VERSION ""

NS_ :

BS_:

BU_:

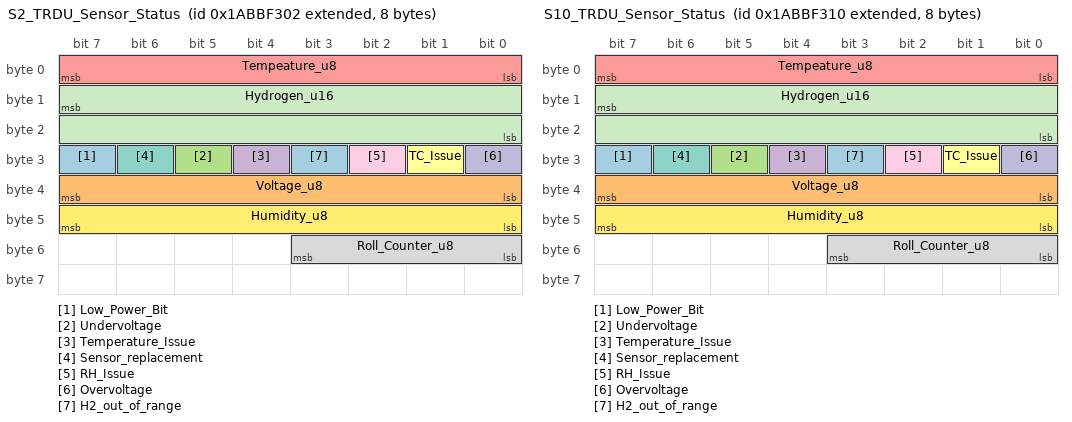
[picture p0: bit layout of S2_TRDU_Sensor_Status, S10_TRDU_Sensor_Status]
BO_ 2596008706 S2_TRDU_Sensor_Status: 8 Vector__XXX
 SG_ Low_Power_Bit : 31|1@1+ (1,0) [0|0] "" Vector__XXX
 SG_ Voltage_u8 : 39|8@0+ (0.2,0) [0|25.5] "V" Vector__XXX
 SG_ Undervoltage : 29|1@1+ (1,0) [0|0] "" Vector__XXX
 SG_ Temperature_Issue : 28|1@1+ (1,0) [0|0] "" Vector__XXX
 SG_ Tempeature_u8 : 0|8@1+ (1,-55) [-55|195] "°C" Vector__XXX
 SG_ TC_Issue : 25|1@1+ (1,0) [0|0] "" Vector__XXX
 SG_ Sensor_replacement : 30|1@1+ (1,0) [0|0] "" Vector__XXX
 SG_ Roll_Counter_u8 : 51|4@0+ (1,0) [0|15] "" Vector__XXX
 SG_ RH_Issue : 26|1@1+ (1,0) [0|0] "" Vector__XXX
 SG_ Overvoltage : 24|1@1+ (1,0) [0|0] "" Vector__XXX
 SG_ Hydrogen_u16 : 15|16@0+ (0.01,0) [0|100] "%" Vector__XXX
 SG_ Humidity_u8 : 47|8@0+ (0.5,0) [0|100] "%" Vector__XXX
 SG_ H2_out_of_range : 27|1@1+ (1,0) [0|0] "" Vector__XXX

BO_ 2596008720 S10_TRDU_Sensor_Status: 8 Vector__XXX
 SG_ Low_Power_Bit : 31|1@1+ (1,0) [0|0] "" Vector__XXX
 SG_ Voltage_u8 : 39|8@0+ (0.2,0) [0|25.5] "V" Vector__XXX
 SG_ Undervoltage : 29|1@1+ (1,0) [0|0] "" Vector__XXX
 SG_ Temperature_Issue : 28|1@1+ (1,0) [0|0] "" Vector__XXX
 SG_ Tempeature_u8 : 0|8@1+ (1,-55) [-55|195] "°C" Vector__XXX
 SG_ TC_Issue : 25|1@1+ (1,0) [0|0] "" Vector__XXX
 SG_ Sensor_replacement : 30|1@1+ (1,0) [0|0] "" Vector__XXX
 SG_ Roll_Counter_u8 : 51|4@0+ (1,0) [0|15] "" Vector__XXX
 SG_ RH_Issue : 26|1@1+ (1,0) [0|0] "" Vector__XXX
 SG_ Overvoltage : 24|1@1+ (1,0) [0|0] "" Vector__XXX
 SG_ Hydrogen_u16 : 15|16@0+ (0.01,0) [0|100] "%" Vector__XXX
 SG_ Humidity_u8 : 47|8@0+ (0.5,0) [0|100] "%" Vector__XXX
 SG_ H2_out_of_range : 27|1@1+ (1,0) [0|0] "" Vector__XXX

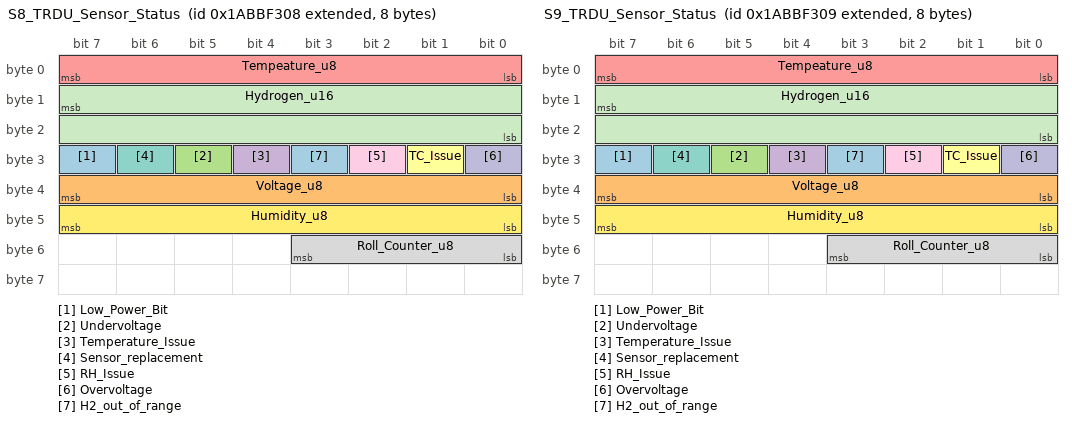
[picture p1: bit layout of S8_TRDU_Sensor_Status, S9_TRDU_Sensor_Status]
BO_ 2596008712 S8_TRDU_Sensor_Status: 8 Vector__XXX
 SG_ Low_Power_Bit : 31|1@1+ (1,0) [0|0] "" Vector__XXX
 SG_ Voltage_u8 : 39|8@0+ (0.2,0) [0|25.5] "V" Vector__XXX
 SG_ Undervoltage : 29|1@1+ (1,0) [0|0] "" Vector__XXX
 SG_ Temperature_Issue : 28|1@1+ (1,0) [0|0] "" Vector__XXX
 SG_ Tempeature_u8 : 0|8@1+ (1,-55) [-55|195] "°C" Vector__XXX
 SG_ TC_Issue : 25|1@1+ (1,0) [0|0] "" Vector__XXX
 SG_ Sensor_replacement : 30|1@1+ (1,0) [0|0] "" Vector__XXX
 SG_ Roll_Counter_u8 : 51|4@0+ (1,0) [0|15] "" Vector__XXX
 SG_ RH_Issue : 26|1@1+ (1,0) [0|0] "" Vector__XXX
 SG_ Overvoltage : 24|1@1+ (1,0) [0|0] "" Vector__XXX
 SG_ Hydrogen_u16 : 15|16@0+ (0.01,0) [0|100] "%" Vector__XXX
 SG_ Humidity_u8 : 47|8@0+ (0.5,0) [0|100] "%" Vector__XXX
 SG_ H2_out_of_range : 27|1@1+ (1,0) [0|0] "" Vector__XXX

BO_ 2596008713 S9_TRDU_Sensor_Status: 8 Vector__XXX
 SG_ Low_Power_Bit : 31|1@1+ (1,0) [0|0] "" Vector__XXX
 SG_ Voltage_u8 : 39|8@0+ (0.2,0) [0|25.5] "V" Vector__XXX
 SG_ Undervoltage : 29|1@1+ (1,0) [0|0] "" Vector__XXX
 SG_ Temperature_Issue : 28|1@1+ (1,0) [0|0] "" Vector__XXX
 SG_ Tempeature_u8 : 0|8@1+ (1,-55) [-55|195] "°C" Vector__XXX
 SG_ TC_Issue : 25|1@1+ (1,0) [0|0] "" Vector__XXX
 SG_ Sensor_replacement : 30|1@1+ (1,0) [0|0] "" Vector__XXX
 SG_ Roll_Counter_u8 : 51|4@0+ (1,0) [0|15] "" Vector__XXX
 SG_ RH_Issue : 26|1@1+ (1,0) [0|0] "" Vector__XXX
 SG_ Overvoltage : 24|1@1+ (1,0) [0|0] "" Vector__XXX
 SG_ Hydrogen_u16 : 15|16@0+ (0.01,0) [0|100] "%" Vector__XXX
 SG_ Humidity_u8 : 47|8@0+ (0.5,0) [0|100] "%" Vector__XXX
 SG_ H2_out_of_range : 27|1@1+ (1,0) [0|0] "" Vector__XXX

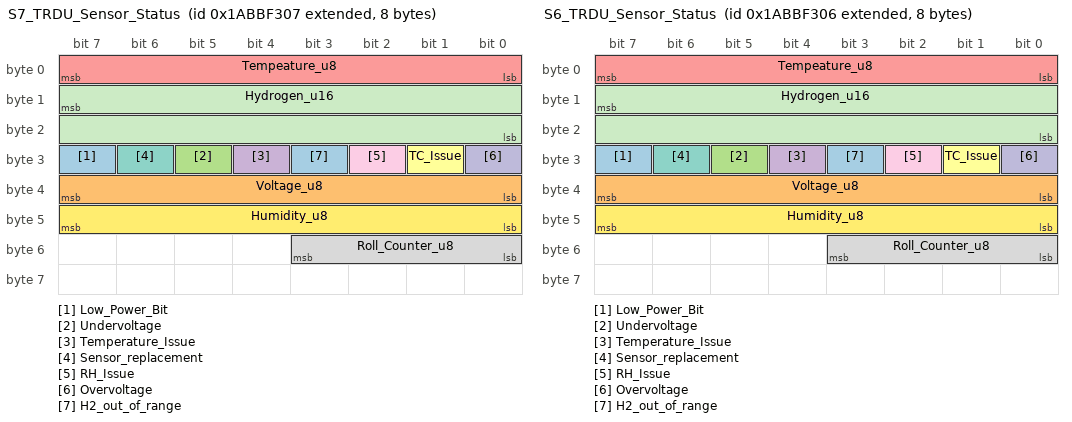
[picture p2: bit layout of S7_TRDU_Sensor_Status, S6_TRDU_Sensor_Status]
BO_ 2596008711 S7_TRDU_Sensor_Status: 8 Vector__XXX
 SG_ Low_Power_Bit : 31|1@1+ (1,0) [0|0] "" Vector__XXX
 SG_ Voltage_u8 : 39|8@0+ (0.2,0) [0|25.5] "V" Vector__XXX
 SG_ Undervoltage : 29|1@1+ (1,0) [0|0] "" Vector__XXX
 SG_ Temperature_Issue : 28|1@1+ (1,0) [0|0] "" Vector__XXX
 SG_ Tempeature_u8 : 0|8@1+ (1,-55) [-55|195] "°C" Vector__XXX
 SG_ TC_Issue : 25|1@1+ (1,0) [0|0] "" Vector__XXX
 SG_ Sensor_replacement : 30|1@1+ (1,0) [0|0] "" Vector__XXX
 SG_ Roll_Counter_u8 : 51|4@0+ (1,0) [0|15] "" Vector__XXX
 SG_ RH_Issue : 26|1@1+ (1,0) [0|0] "" Vector__XXX
 SG_ Overvoltage : 24|1@1+ (1,0) [0|0] "" Vector__XXX
 SG_ Hydrogen_u16 : 15|16@0+ (0.01,0) [0|100] "%" Vector__XXX
 SG_ Humidity_u8 : 47|8@0+ (0.5,0) [0|100] "%" Vector__XXX
 SG_ H2_out_of_range : 27|1@1+ (1,0) [0|0] "" Vector__XXX

BO_ 2596008710 S6_TRDU_Sensor_Status: 8 Vector__XXX
 SG_ Low_Power_Bit : 31|1@1+ (1,0) [0|0] "" Vector__XXX
 SG_ Voltage_u8 : 39|8@0+ (0.2,0) [0|25.5] "V" Vector__XXX
 SG_ Undervoltage : 29|1@1+ (1,0) [0|0] "" Vector__XXX
 SG_ Temperature_Issue : 28|1@1+ (1,0) [0|0] "" Vector__XXX
 SG_ Tempeature_u8 : 0|8@1+ (1,-55) [-55|195] "°C" Vector__XXX
 SG_ TC_Issue : 25|1@1+ (1,0) [0|0] "" Vector__XXX
 SG_ Sensor_replacement : 30|1@1+ (1,0) [0|0] "" Vector__XXX
 SG_ Roll_Counter_u8 : 51|4@0+ (1,0) [0|15] "" Vector__XXX
 SG_ RH_Issue : 26|1@1+ (1,0) [0|0] "" Vector__XXX
 SG_ Overvoltage : 24|1@1+ (1,0) [0|0] "" Vector__XXX
 SG_ Hydrogen_u16 : 15|16@0+ (0.01,0) [0|100] "%" Vector__XXX
 SG_ Humidity_u8 : 47|8@0+ (0.5,0) [0|100] "%" Vector__XXX
 SG_ H2_out_of_range : 27|1@1+ (1,0) [0|0] "" Vector__XXX

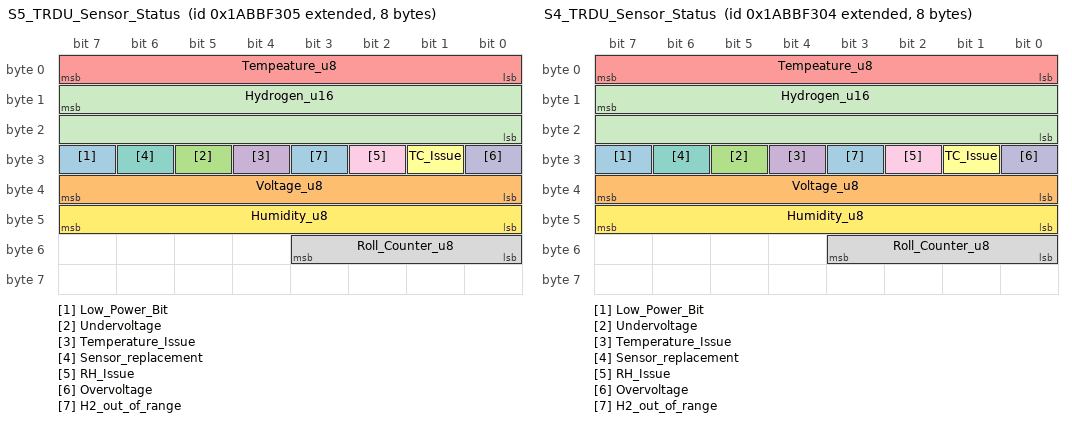
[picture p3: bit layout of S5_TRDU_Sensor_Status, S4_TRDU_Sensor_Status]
BO_ 2596008709 S5_TRDU_Sensor_Status: 8 Vector__XXX
 SG_ Low_Power_Bit : 31|1@1+ (1,0) [0|0] "" Vector__XXX
 SG_ Voltage_u8 : 39|8@0+ (0.2,0) [0|25.5] "V" Vector__XXX
 SG_ Undervoltage : 29|1@1+ (1,0) [0|0] "" Vector__XXX
 SG_ Temperature_Issue : 28|1@1+ (1,0) [0|0] "" Vector__XXX
 SG_ Tempeature_u8 : 0|8@1+ (1,-55) [-55|195] "°C" Vector__XXX
 SG_ TC_Issue : 25|1@1+ (1,0) [0|0] "" Vector__XXX
 SG_ Sensor_replacement : 30|1@1+ (1,0) [0|0] "" Vector__XXX
 SG_ Roll_Counter_u8 : 51|4@0+ (1,0) [0|15] "" Vector__XXX
 SG_ RH_Issue : 26|1@1+ (1,0) [0|0] "" Vector__XXX
 SG_ Overvoltage : 24|1@1+ (1,0) [0|0] "" Vector__XXX
 SG_ Hydrogen_u16 : 15|16@0+ (0.01,0) [0|100] "%" Vector__XXX
 SG_ Humidity_u8 : 47|8@0+ (0.5,0) [0|100] "%" Vector__XXX
 SG_ H2_out_of_range : 27|1@1+ (1,0) [0|0] "" Vector__XXX

BO_ 2596008708 S4_TRDU_Sensor_Status: 8 Vector__XXX
 SG_ Low_Power_Bit : 31|1@1+ (1,0) [0|0] "" Vector__XXX
 SG_ Voltage_u8 : 39|8@0+ (0.2,0) [0|25.5] "V" Vector__XXX
 SG_ Undervoltage : 29|1@1+ (1,0) [0|0] "" Vector__XXX
 SG_ Temperature_Issue : 28|1@1+ (1,0) [0|0] "" Vector__XXX
 SG_ Tempeature_u8 : 0|8@1+ (1,-55) [-55|195] "°C" Vector__XXX
 SG_ TC_Issue : 25|1@1+ (1,0) [0|0] "" Vector__XXX
 SG_ Sensor_replacement : 30|1@1+ (1,0) [0|0] "" Vector__XXX
 SG_ Roll_Counter_u8 : 51|4@0+ (1,0) [0|15] "" Vector__XXX
 SG_ RH_Issue : 26|1@1+ (1,0) [0|0] "" Vector__XXX
 SG_ Overvoltage : 24|1@1+ (1,0) [0|0] "" Vector__XXX
 SG_ Hydrogen_u16 : 15|16@0+ (0.01,0) [0|100] "%" Vector__XXX
 SG_ Humidity_u8 : 47|8@0+ (0.5,0) [0|100] "%" Vector__XXX
 SG_ H2_out_of_range : 27|1@1+ (1,0) [0|0] "" Vector__XXX

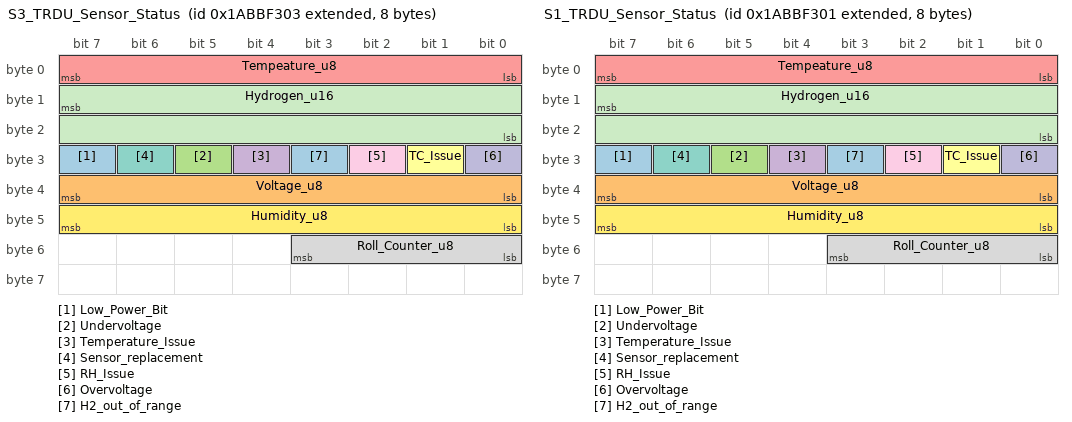
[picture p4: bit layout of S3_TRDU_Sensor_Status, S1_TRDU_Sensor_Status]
BO_ 2596008707 S3_TRDU_Sensor_Status: 8 Vector__XXX
 SG_ Low_Power_Bit : 31|1@1+ (1,0) [0|0] "" Vector__XXX
 SG_ Voltage_u8 : 39|8@0+ (0.2,0) [0|25.5] "V" Vector__XXX
 SG_ Undervoltage : 29|1@1+ (1,0) [0|0] "" Vector__XXX
 SG_ Temperature_Issue : 28|1@1+ (1,0) [0|0] "" Vector__XXX
 SG_ Tempeature_u8 : 0|8@1+ (1,-55) [-55|195] "°C" Vector__XXX
 SG_ TC_Issue : 25|1@1+ (1,0) [0|0] "" Vector__XXX
 SG_ Sensor_replacement : 30|1@1+ (1,0) [0|0] "" Vector__XXX
 SG_ Roll_Counter_u8 : 51|4@0+ (1,0) [0|15] "" Vector__XXX
 SG_ RH_Issue : 26|1@1+ (1,0) [0|0] "" Vector__XXX
 SG_ Overvoltage : 24|1@1+ (1,0) [0|0] "" Vector__XXX
 SG_ Hydrogen_u16 : 15|16@0+ (0.01,0) [0|100] "%" Vector__XXX
 SG_ Humidity_u8 : 47|8@0+ (0.5,0) [0|100] "%" Vector__XXX
 SG_ H2_out_of_range : 27|1@1+ (1,0) [0|0] "" Vector__XXX

BO_ 2596008705 S1_TRDU_Sensor_Status: 8 Vector__XXX
 SG_ Low_Power_Bit : 31|1@1+ (1,0) [0|0] "" Vector__XXX
 SG_ Voltage_u8 : 39|8@0+ (0.2,0) [0|25.5] "V" Vector__XXX
 SG_ Undervoltage : 29|1@1+ (1,0) [0|0] "" Vector__XXX
 SG_ Temperature_Issue : 28|1@1+ (1,0) [0|0] "" Vector__XXX
 SG_ Tempeature_u8 : 0|8@1+ (1,-55) [-55|195] "°C" Vector__XXX
 SG_ TC_Issue : 25|1@1+ (1,0) [0|0] "" Vector__XXX
 SG_ Sensor_replacement : 30|1@1+ (1,0) [0|0] "" Vector__XXX
 SG_ Roll_Counter_u8 : 51|4@0+ (1,0) [0|15] "" Vector__XXX
 SG_ RH_Issue : 26|1@1+ (1,0) [0|0] "" Vector__XXX
 SG_ Overvoltage : 24|1@1+ (1,0) [0|0] "" Vector__XXX
 SG_ Hydrogen_u16 : 15|16@0+ (0.01,0) [0|100] "%" Vector__XXX
 SG_ Humidity_u8 : 47|8@0+ (0.5,0) [0|100] "%" Vector__XXX
 SG_ H2_out_of_range : 27|1@1+ (1,0) [0|0] "" Vector__XXX

BA_DEF_  "BusType" STRING ;
BA_DEF_DEF_  "BusType" "CAN";
